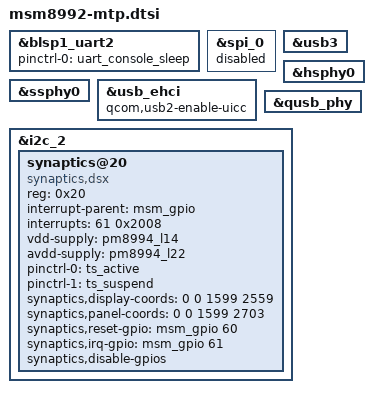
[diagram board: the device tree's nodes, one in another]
/* Copyright (c) 2014, The Linux Foundation. All rights reserved.
 *
 * This program is free software; you can redistribute it and/or modify
 * it under the terms of the GNU General Public License version 2 and
 * only version 2 as published by the Free Software Foundation.
 *
 * This program is distributed in the hope that it will be useful,
 * but WITHOUT ANY WARRANTY; without even the implied warranty of
 * MERCHANTABILITY or FITNESS FOR A PARTICULAR PURPOSE.  See the
 * GNU General Public License for more details.
 */

#include "msm8992-pinctrl.dtsi"

&blsp1_uart2 {
	status= "ok";
	pinctrl-names = "default";
	pinctrl-0 = <&uart_console_sleep>;
};

&spi_0 {
	status = "disabled";
};

&usb3 {
	status = "ok";
};

&hsphy0 {
	status = "ok";
};

&ssphy0 {
	status = "ok";
};

&usb_ehci {
	status = "ok";
	qcom,usb2-enable-uicc;
};

&qusb_phy {
	status = "ok";
};

&i2c_2 {
	synaptics@20 {
		compatible = "synaptics,dsx";
		reg = <0x20>;
		interrupt-parent = <&msm_gpio>;
		interrupts = <61 0x2008>;
		vdd-supply = <&pm8994_l14>;
		avdd-supply = <&pm8994_l22>;
		pinctrl-names = "pmx_ts_active", "pmx_ts_suspend";
		pinctrl-0 = <&ts_active>;
		pinctrl-1 = <&ts_suspend>;
		synaptics,display-coords = <0 0 1599 2559>;
		synaptics,panel-coords = <0 0 1599 2703>;
		synaptics,reset-gpio = <&msm_gpio 60 0x00>;
		synaptics,irq-gpio = <&msm_gpio 61 0x00>;
		synaptics,disable-gpios;
	};
};
